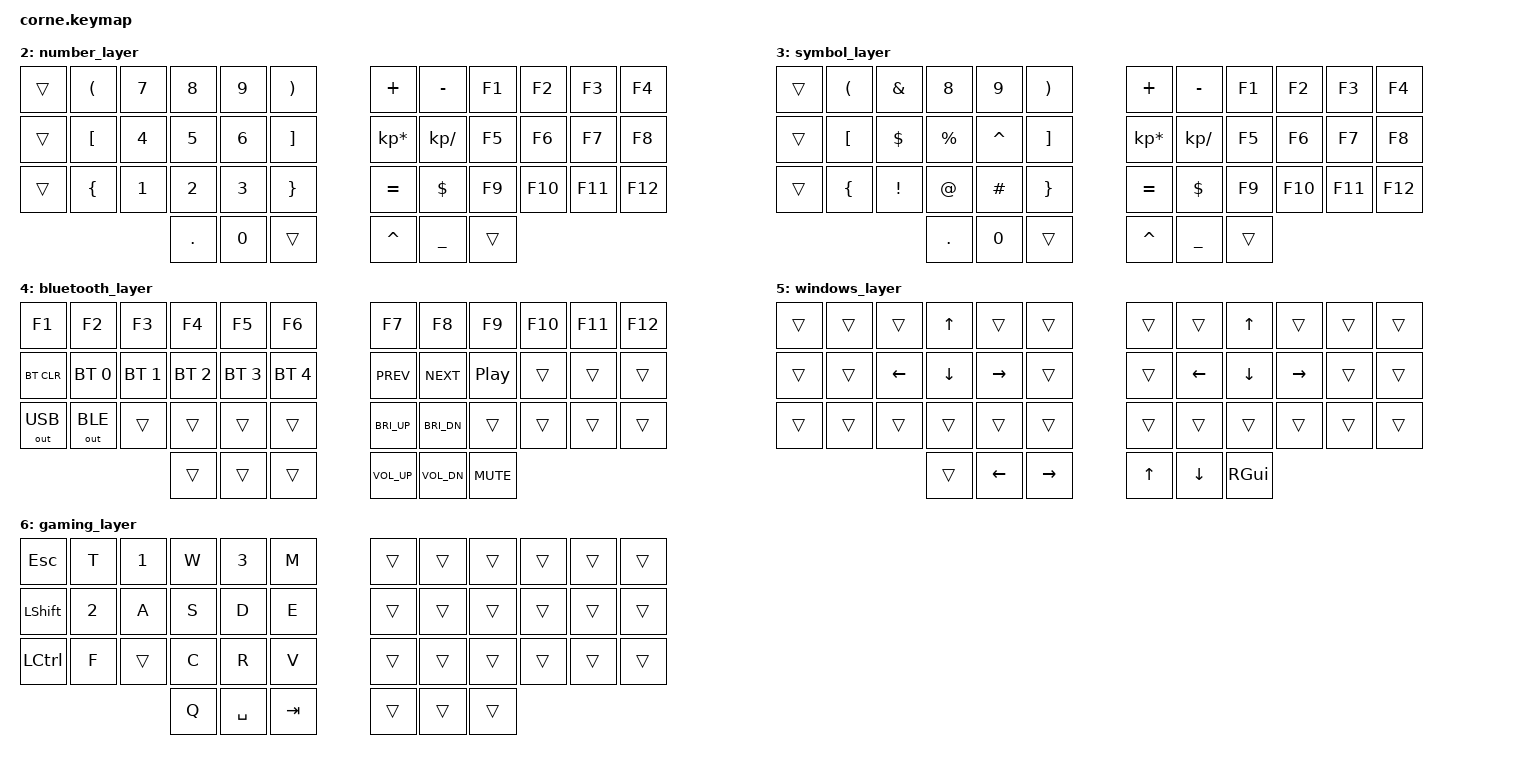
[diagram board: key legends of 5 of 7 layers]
/*
 * Copyright (c) 2020 The ZMK Contributors
 *
 * SPDX-License-Identifier: MIT
 */

#include <behaviors.dtsi>
#include <dt-bindings/zmk/keys.h>
#include <dt-bindings/zmk/bt.h>
#include <dt-bindings/zmk/outputs.h>
#include <dt-bindings/zmk/behaviors.h>

// Home row mods macro
#define HRML(k2,k3,k4) &ht LALT k2  &ht TAB k3  &ht LGUI k4
#define HRMR(k1,k2,k3) &ht RGUI k1  &ht TAB k2  &ht RALT k3

#define Def 0
#define Col 1
#define Num 2
#define Sym 3
#define Func 4
#define WinMan 5
#define Gam 6


/ {
    combos {
        compatible = "zmk,combos";
        combo_bkslash {
            timeout-ms = <50>;
            key-positions = <15 38>;
            bindings = <&ht PIPE BACKSLASH>;
        };
        combo_cap {
            timeout-ms = <50>;
            key-positions = <38 39>;
            bindings = <&kp CAPS>;
        };
        combo_dllr {
            timeout-ms = <50>;
            key-positions = <14 38>;
            bindings = <&kp DLLR>;
        };
        combo_del {
            timeout-ms = <50>;
            key-positions = <13 25>;
            bindings = <&kp DEL>;
        };
        combo_bspc {
            timeout-ms = <50>;
            key-positions = <22 34>;
            bindings = <&kp BSPC>;
        };
        combo_col {
            timeout-ms = <50>;
            key-positions = <15 16 19 20>;
            bindings = <&tog Col>;
        };
        combo_sym {
            timeout-ms = <50>;
            key-positions = <0 12 24>;
            bindings = <&sl Sym>;
        };
        combo_Gam {
            timeout-ms = <50>;
            key-positions = <13 17 18 20>;
            bindings = <&tog Gam>;
        };
    };
};



/ {
    macros {
        backwhole: zed_em_kay {
            label = "ZM_zed_em_kay";
            compatible = "zmk,behavior-macro";
            #binding-cells = <0>;
            bindings
                = <&macro_press &kp LCTRL>
                , <&macro_press &kp BSPC>
                , <&macro_release &kp LCTRL>
                , <&macro_release &kp BSPC>
                ;
        };
    };
};


/ {
    behaviors {
        ht: hold_tap {
            label = "hold_tap";
            compatible = "zmk,behavior-hold-tap";
            #binding-cells = <2>;
            flavor = "tap-preferred";
            tapping-term-ms = <220>;
            quick-tap-ms = <150>;
            global-quick-tap;
            bindings = <&kp>, <&kp>;
        };
    };
        keymap {
                compatible = "zmk,keymap";
                default_layer {
                        bindings = <
        //╭────────────────┬────────────┬────────────┬────────────┬────────────┬──────────────╮   ╭────────────┬───────────────┬────────────────┬─────────────┬────────────┬───────────────╮
        //│  DEL           │  Q         │  W         │  E         │  R         │  T           │   │  Y         │  U            │  I             │  O          │  P         │  -            │
            &lt WinMan DEL   &kp Q        &kp W        &kp E        &kp R        &kp T              &kp Y        &kp U           &kp I            &kp O         &kp P        &kp MINUS   
        //├────────────────┼────────────┼────────────┼────────────┼────────────┼──────────────┤   ├────────────┼───────────────┼────────────────┼─────────────┼────────────┼───────────────┤
        //│  SHFT          │  A         │  S         │  D         │  F         │  G           │   │  H         │  J            │  K             │  L          │  ; :       │  ' "          │
            &sk LSHFT        &kp A        HRML(S,      D,           F)           &kp G              &kp H        HRMR(J,         K,               L)            &kp SEMI     &kp SQT    
        //├────────────────┼────────────┼────────────┼────────────┼────────────┼──────────────┤   ├────────────┼───────────────┼────────────────┼─────────────┼────────────┼───────────────┤
        //│  CTRL          │  Z         │  X         │  C         │  V         │  B           │   │  N         │  M            │ , <            │ . >         │ / ?        │  ESC          │
            &mt LCTRL GRAVE  &kp Z        &kp X        &kp C        &kp V        &kp B              &kp N        &kp M           &kp COMMA        &kp DOT       &kp FSLH     &lt Func ESC   
        //╰────────────────┴────────────┴────────────┼────────────┼────────────┼──────────────┤   ├────────────┼───────────────┼────────────────┼─────────────┴────────────┴───────────────╯
                                                       &kp BSPC     &kp SPACE    &lt Num ENTER      &kp ENTER    &lt WinMan SPACE   &kp BSPC
        //                                           ╰────────────┴────────────┴──────────────╯   ╰────────────┴───────────────┴────────────────╯
                        >;
                };
                colemakdh_layer {
                        bindings = <
        //╭────────────────┬────────────┬────────────┬────────────┬────────────┬──────────────╮   ╭────────────┬───────────────┬────────────────┬─────────────┬────────────┬───────────────╮
        //│  DEL           │  Q         │  W         │  F         │  P         │  B           │   │  J         │  L            │  U             │  Y          │  ; :       │  -            │
            &lt WinMan DEL   &kp Q        &kp W        &kp F        &kp P        &kp B              &kp J        &kp L           &kp U            &kp Y         &kp SEMI     &kp MINUS   
        //├────────────────┼────────────┼────────────┼────────────┼────────────┼──────────────┤   ├────────────┼───────────────┼────────────────┼─────────────┼────────────┼───────────────┤
        //│  SHFT          │  A         │  R         │  S         │  T         │  G           │   │  M         │  N            │  E             │  I          │  O         │  ' "          │
            &sk LSHFT        &kp A        HRML(R,      S,           T)           &kp G              &kp M        HRMR(N,         E,               I)            &kp O        &kp SQT    
        //├────────────────┼────────────┼────────────┼────────────┼────────────┼──────────────┤   ├────────────┼───────────────┼────────────────┼─────────────┼────────────┼───────────────┤
        //│  CTRL          │  Z         │  X         │  C         │  D         │  V           │   │  K         │  H            │  , <           │  . >        │  / ?       │  ESC          │
            &mt LCTRL GRAVE  &kp Z        &kp X        &kp C        &kp D        &kp V              &kp K        &kp H           &kp COMMA        &kp DOT       &kp FSLH     &lt Func ESC   
        //╰────────────────┴────────────┴────────────┼────────────┼────────────┼──────────────┤   ├────────────┼───────────────┼────────────────┼─────────────┴────────────┴───────────────╯
                                                       &kp BSPC     &kp SPACE    &lt Num ENTER      &kp ENTER    &lt WinMan SPACE   &kp BSPC 
        //                                           ╰────────────┴────────────┴──────────────╯   ╰────────────┴───────────────┴────────────────╯
                        >;
                };
                number_layer {
                        bindings = <
        //╭────────────┬────────────┬────────────┬────────────┬────────────┬────────────╮   ╭─────────────────┬───────────────┬────────────┬────────────┬────────────┬─────────────╮
        //│            │  (         │  7         │  8         │  9         │  )         │   │  +              │  -            │  F1        │  F2        │  F3        │  F4         │
            &trans       &kp LPAR     &kp N7       &kp N8       &kp N9       &kp RPAR         &kp PLUS          &kp MINUS       &kp F1      &kp F2       &kp F3       &kp F4      
        //├────────────┼────────────┼────────────┼────────────┼────────────┼────────────┤   ├─────────────────┼───────────────┼────────────┼────────────┼────────────┼─────────────┤
        //│            │  [         │  4         │  5         │  6         │  ]         │   │  *              │  /            │  F5        │  F6        │  F7        │  F8         │
            &trans       &kp LBKT     &kp N4       &kp N5       &kp N6       &kp RBKT         &kp KP_MULTIPLY   &kp KP_DIVIDE   &kp F5       &kp F6       &kp F7       &kp F8      
        //├────────────┼────────────┼────────────┼────────────┼────────────┼────────────┤   ├─────────────────┼───────────────┼────────────┼────────────┼────────────┼─────────────┤
        //│            │  {         │  1         │  2         │  3         │  }         │   │  =              │  $            │  F9        │  F10       │  F11       │  F12        │
            &trans       &kp LBRC     &kp N1       &kp N2       &kp N3       &kp RBRC         &kp EQUAL         &kp DLLR        &kp F9       &kp F10      &kp F11      &kp F12     
        //╰────────────┴────────────┴────────────┼────────────┼────────────┼────────────┤   ├─────────────────┼───────────────┼────────────┼────────────┴────────────┴─────────────╯
                                                   &kp DOT      &kp N0       &trans           &kp CARET         &kp UNDER       &trans
        //                                       ╰────────────┴────────────┴────────────╯   ╰─────────────────┴───────────────┴────────────╯
                        >;
                };
                symbol_layer {
                        bindings = <
        //╭────────────┬────────────┬────────────┬────────────┬────────────┬────────────╮   ╭─────────────────┬───────────────┬────────────┬────────────┬────────────┬─────────────╮
        //│            │  (         │  &         │  8         │  9         │  )         │   │  +              │  -            │  F1        │  F2        │  F3        │  F4         │
            &trans       &kp LPAR     &kp AMPS     &kp N8       &kp N9       &kp RPAR          &kp PLUS         &kp MINUS        &kp F1       &kp F2       &kp F3       &kp F4      
        //├────────────┼────────────┼────────────┼────────────┼────────────┼────────────┤   ├─────────────────┼───────────────┼────────────┼────────────┼────────────┼─────────────┤
        //│            │  [         │  $         │  %         │  ^         │  ]         │   │  *              │  /            │  F5        │  F6        │  F7        │  F8         │
            &trans       &kp LBKT     &kp DLLR     &kp PRCNT    &kp CARET    &kp RBKT          &kp KP_MULTIPLY  &kp KP_DIVIDE    &kp F5       &kp F6       &kp F7       &kp F8      
        //├────────────┼────────────┼────────────┼────────────┼────────────┼────────────┤   ├─────────────────┼───────────────┼────────────┼────────────┼────────────┼─────────────┤
        //│            │  {         │  !         │  @         │  #         │  }         │   │  =              │  $            │  F9        │  F10       │  F11       │  F12        │
            &trans       &kp LBRC     &kp EXCL     &kp AT       &kp HASH     &kp RBRC          &kp EQUAL        &kp DLLR         &kp F9       &kp F10      &kp F11      &kp F12     
        //╰────────────┴────────────┴────────────┼────────────┼────────────┼────────────┤   ├─────────────────┼───────────────┼────────────┼────────────┴────────────┴─────────────╯
                                                   &kp DOT      &kp N0       &trans           &kp CARET         &kp UNDER       &trans
        //                                       ╰────────────┴────────────┴────────────╯   ╰─────────────────┴───────────────┴────────────╯
                        >;
                };
                bluetooth_layer {
                        bindings = <
        //╭─────────────┬──────────────┬──────────────┬──────────────┬──────────────┬──────────────╮   ╭───────────────┬───────────────┬────────────┬─────────────┬────────────┬───────────╮
        //│  F1         │  F2          │  F3          │  F4          │  F5          │  F6          │   │  F7           │  F8           │  F9        │  F10        │  F11       │  F12      │
            &kp F1        &kp F2         &kp F3         &kp F4         &kp F5         &kp F6             &kp F7          &kp F8          &kp F9       &kp F10       &kp F11      &kp F12    
        //├─────────────┼──────────────┼──────────────┼──────────────┼──────────────┼──────────────┤   ├───────────────┼───────────────┼────────────┼─────────────┼────────────┼───────────┤
        //│  BT clear   │  BT0         │  BT1         │  BT2         │  BT3         │  BT4         │   │  PREV         │  NEXT         │  PLAY      │             │            │           │
            &bt BT_CLR    &bt BT_SEL 0   &bt BT_SEL 1   &bt BT_SEL 2   &bt BT_SEL 3   &bt BT_SEL 4       &kp C_PREV      &kp C_NEXT      &kp C_PP     &trans        &trans       &trans    
        //├─────────────┼──────────────┼──────────────┼──────────────┼──────────────┼──────────────┤   ├───────────────┼───────────────┼────────────┼─────────────┼────────────┼───────────┤
        //│             │              │              │              │              │              │   │  BRIGHT       │  DIM          │            │             │            │           │
            &out OUT_USB  &out OUT_BLE   &trans         &trans         &trans         &trans             &kp C_BRI_UP    &kp C_BRI_DN    &trans       &trans        &trans       &trans   
        //╰─────────────┴──────────────┴──────────────┼──────────────┼──────────────┼──────────────┤   ├───────────────┼───────────────┼────────────┼─────────────┴────────────┴───────────╯
                                                        &trans         &trans         &trans             &kp C_VOL_UP    &kp C_VOL_DN    &kp C_MUTE
        //                                            ╰──────────────┴──────────────┴──────────────╯   ╰───────────────┴───────────────┴────────────╯
                        >;
                };
                windows_layer {
                        bindings = <
        //╭─────────────┬─────────────┬─────────────┬─────────────┬─────────────┬─────────────╮   ╭───────────────┬───────────────┬────────────┬─────────────┬────────────┬───────────╮
        //│             │             │             │             │             │             │   │               │               │  up        │             │            │           │
            &trans        &trans        &trans        &kp UP        &trans        &trans            &trans          &trans          &kp UP       &trans        &trans       &trans    
        //├─────────────┼─────────────┼─────────────┼─────────────┼─────────────┼─────────────┤   ├───────────────┼───────────────┼────────────┼─────────────┼────────────┼───────────┤
        //│             │             │             │             │             │             │   │               │  left         │  down      │  right      │            │           │
            &trans        &trans        &kp LEFT      &kp DOWN      &kp RIGHT        &trans         &trans          &kp LEFT        &kp DOWN     &kp RIGHT     &trans       &trans    
        //├─────────────┼─────────────┼─────────────┼─────────────┼─────────────┼─────────────┤   ├───────────────┼───────────────┼────────────┼─────────────┼────────────┼───────────┤
        //│             │             │             │             │             │             │   │               │               │            │             │            │           │
            &trans        &trans        &trans        &trans        &trans        &trans            &trans          &trans          &trans       &trans        &trans       &trans      
        //╰─────────────┴─────────────┴─────────────┼─────────────┼─────────────┼─────────────┤   ├───────────────┼───────────────┼────────────┼─────────────┴────────────┴───────────╯
                                                      &trans        &kp LEFT      &kp RIGHT         &kp UP          &kp DOWN        &kp RGUI
        //                                          ╰─────────────┴─────────────┴─────────────╯   ╰───────────────┴───────────────┴────────────╯
                        >;
                };
                gaming_layer {
                        bindings = <
        //╭─────────────┬─────────────┬─────────────┬─────────────┬─────────────┬─────────────╮   ╭───────────────┬───────────────┬────────────┬─────────────┬────────────┬───────────╮
        //│             │             │             │             │             │             │   │               │               │            │             │            │           │
            &kp ESC       &kp T         &kp N1        &kp W         &kp N3        &kp M             &trans          &trans          &trans       &trans        &trans       &trans    
        //├─────────────┼─────────────┼─────────────┼─────────────┼─────────────┼─────────────┤   ├───────────────┼───────────────┼────────────┼─────────────┼────────────┼───────────┤
        //│             │             │             │             │             │             │   │               │               │            │             │            │           │
            &kp LSHFT     &kp N2        &kp A         &kp S         &kp D         &kp E             &trans          &trans          &trans       &trans        &trans       &trans    
        //├─────────────┼─────────────┼─────────────┼─────────────┼─────────────┼─────────────┤   ├───────────────┼───────────────┼────────────┼─────────────┼────────────┼───────────┤
        //│             │             │             │             │             │             │   │               │               │            │             │            │           │
            &kp LCTRL     &kp F         &trans        &kp C         &kp R         &kp V             &trans          &trans          &trans       &trans        &trans       &trans      
        //╰─────────────┴─────────────┴─────────────┼─────────────┼─────────────┼─────────────┤   ├───────────────┼───────────────┼────────────┼─────────────┴────────────┴───────────╯
                                                      &kp Q         &kp SPACE     &kp TAB           &trans          &trans          &trans
        //                                          ╰─────────────┴─────────────┴─────────────╯   ╰───────────────┴───────────────┴────────────╯
                        >;
                };
        };
};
